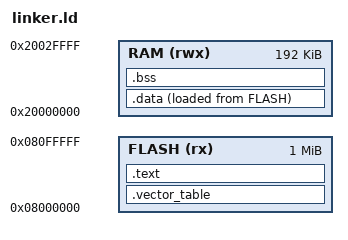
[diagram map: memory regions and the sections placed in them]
MEMORY {
  FLASH (rx) : ORIGIN = 0x08000000, LENGTH = 1024K
  RAM   (rwx): ORIGIN = 0x20000000, LENGTH = 192K
}

ENTRY(Reset_Handler)

SECTIONS {
  .vector_table : {
    . = ALIGN(4);
    KEEP(*(.vector_table))
  } > FLASH

  .text : {
    *(.text*)
    *(.rodata*)
  } > FLASH

  .data : {
    _sdata = .;
    *(.data*)
    _edata = .;
  } > RAM AT > FLASH
  _sidata = LOADADDR(.data);

  .bss : {
    _sbss = .;
    *(.bss*)
    *(COMMON)
    _ebss = .;
  } > RAM

  _estack = ORIGIN(RAM) + LENGTH(RAM);
}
